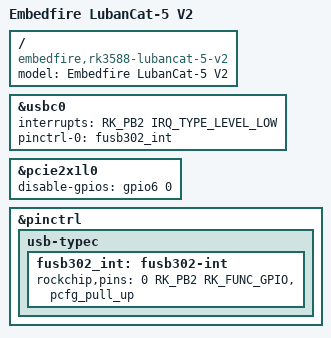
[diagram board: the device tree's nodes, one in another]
// SPDX-License-Identifier: (GPL-2.0+ OR MIT)
/*
 * Copyright (c) 2021 Rockchip Electronics Co., Ltd.
 * Copyright (c) 2023 EmbedFire <embedfire@embedfire.com>
 */

/dts-v1/;

#include "rk3588-lubancat-5.dts"

/ {
	model = "Embedfire LubanCat-5 V2";
	compatible = "embedfire,rk3588-lubancat-5-v2", "rockchip,rk3588";
};

&usbc0 {
    interrupts = <RK_PB2 IRQ_TYPE_LEVEL_LOW>;
    pinctrl-0 = <&fusb302_int>;
};

&pcie2x1l0 {
    disable-gpios = <&gpio6 0 GPIO_ACTIVE_HIGH>;
};

&pinctrl {
    usb-typec {
		fusb302_int: fusb302-int {
			rockchip,pins = <0 RK_PB2 RK_FUNC_GPIO &pcfg_pull_up>;
		};
	};
};
